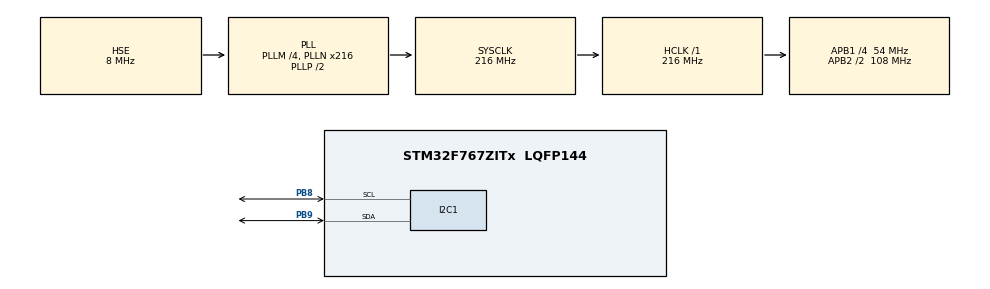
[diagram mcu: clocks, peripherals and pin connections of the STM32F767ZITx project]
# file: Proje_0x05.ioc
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I2C1.Timing=0x20404768
Mcu.Family=STM32F7
Mcu.Name=STM32F767ZITx
Mcu.Package=LQFP144
NVIC.PriorityGroup=NVIC_PRIORITYGROUP_4
PA13.Mode=Serial_Wire
PA13.Signal=SYS_JTMS-SWDIO
PA14.Mode=Serial_Wire
PA14.Signal=SYS_JTCK-SWCLK
PB8.Mode=I2C
PB8.Signal=I2C1_SCL
PB9.Mode=I2C
PB9.Signal=I2C1_SDA
PH0/OSC_IN.Mode=HSE-External-Oscillator
PH0/OSC_IN.Signal=RCC_OSC_IN
PH1/OSC_OUT.Mode=HSE-External-Oscillator
PH1/OSC_OUT.Signal=RCC_OSC_OUT
ProjectManager.HeapSize=0x200
ProjectManager.StackSize=0x400
ProjectManager.TargetToolchain=STM32CubeIDE
RCC.48MHZClocksFreq_Value=24000000
RCC.AHBFreq_Value=216000000
RCC.APB1CLKDivider=RCC_HCLK_DIV4
RCC.APB1Freq_Value=54000000
RCC.APB1TimFreq_Value=108000000
RCC.APB2CLKDivider=RCC_HCLK_DIV2
RCC.APB2Freq_Value=108000000
RCC.APB2TimFreq_Value=216000000
RCC.CortexFreq_Value=216000000
RCC.HCLKFreq_Value=216000000
RCC.HSE_VALUE=8000000
RCC.HSI_VALUE=16000000
RCC.PLLM=4
RCC.PLLMUL=RCC_PLL_MUL9
RCC.PLLN=216
RCC.PLLQ=4
RCC.PLLSourceVirtual=RCC_PLLSOURCE_HSE
RCC.PRESCALERUSB=RCC_USBCLKSOURCE_PLL_DIV1_5
RCC.SYSCLKFreq_VALUE=216000000
RCC.SYSCLKSource=RCC_SYSCLKSOURCE_PLLCLK
RCC.SYSCLKSourceVirtual=RCC_SYSCLKSOURCE_PLLCLK
RCC.USBFreq_Value=108000000
RCC.VCOOutputFreq_Value=432000000
board=NUCLEO-F767ZI

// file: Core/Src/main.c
/* USER CODE BEGIN Header */
/**
 ******************************************************************************
 * @file           : main.c
 * @brief          : Main program body
 ******************************************************************************
 * @attention
 *
 * Copyright (c) 2025 STMicroelectronics.
 * All rights reserved.
 *
 * This software is licensed under terms that can be found in the LICENSE file
 * in the root directory of this software component.
 * If no LICENSE file comes with this software, it is provided AS-IS.
 *
 ******************************************************************************
 */
/* USER CODE END Header */
#include "main.h"

I2C_HandleTypeDef hi2c1;

void SystemClock_Config(void);
static void MX_GPIO_Init(void);
static void MX_I2C1_Init(void);

/* USER CODE BEGIN 0 */
char I2C_Value;
char Read_I2C(char addr) {
	char TX_buff[1];
	char RX_buff[1];
	char I2C_addr = 0xD0;

	TX_buff[0] = addr;

	HAL_I2C_Master_Transmit(&hi2c1, I2C_addr, TX_buff, 1, 10);
	HAL_I2C_Master_Receive(&hi2c1, I2C_addr, RX_buff, 1, 10);

	return RX_buff[0];
}

/* USER CODE END 0 */

int main(void) {

	/* MCU Configuration--------------------------------------------------------*/

	/* Reset of all peripherals, Initializes the Flash interface and the Systick. */
	HAL_Init();

	/* Configure the system clock */
	SystemClock_Config();

	/* Initialize all configured peripherals */
	MX_GPIO_Init();
	MX_I2C1_Init();

	/* Infinite loop */
	while (1) {

		/* USER CODE BEGIN 3 */
		I2C_Value = Read_I2C(0x6B);
		HAL_Delay(500);
		I2C_Value = Read_I2C(0x75);
		HAL_Delay(500);
	}
	/* USER CODE END 3 */
}

void SystemClock_Config(void) {
	RCC_OscInitTypeDef RCC_OscInitStruct = { 0 };
	RCC_ClkInitTypeDef RCC_ClkInitStruct = { 0 };

	/** Configure the main internal regulator output voltage
	 */
	__HAL_RCC_PWR_CLK_ENABLE();
	__HAL_PWR_VOLTAGESCALING_CONFIG(PWR_REGULATOR_VOLTAGE_SCALE1);

	/** Initializes the RCC Oscillators according to the specified parameters
	 * in the RCC_OscInitTypeDef structure.
	 */
	RCC_OscInitStruct.OscillatorType = RCC_OSCILLATORTYPE_HSE;
	RCC_OscInitStruct.HSEState = RCC_HSE_ON;
	RCC_OscInitStruct.PLL.PLLState = RCC_PLL_ON;
	RCC_OscInitStruct.PLL.PLLSource = RCC_PLLSOURCE_HSE;
	RCC_OscInitStruct.PLL.PLLM = 4;
	RCC_OscInitStruct.PLL.PLLN = 216;
	RCC_OscInitStruct.PLL.PLLP = RCC_PLLP_DIV2;
	RCC_OscInitStruct.PLL.PLLQ = 4;
	RCC_OscInitStruct.PLL.PLLR = 2;
	if (HAL_RCC_OscConfig(&RCC_OscInitStruct) != HAL_OK) {
		Error_Handler();
	}

	/** Activate the Over-Drive mode
	 */
	if (HAL_PWREx_EnableOverDrive() != HAL_OK) {
		Error_Handler();
	}

	/** Initializes the CPU, AHB and APB buses clocks
	 */
	RCC_ClkInitStruct.ClockType = RCC_CLOCKTYPE_HCLK | RCC_CLOCKTYPE_SYSCLK
			| RCC_CLOCKTYPE_PCLK1 | RCC_CLOCKTYPE_PCLK2;
	RCC_ClkInitStruct.SYSCLKSource = RCC_SYSCLKSOURCE_PLLCLK;
	RCC_ClkInitStruct.AHBCLKDivider = RCC_SYSCLK_DIV1;
	RCC_ClkInitStruct.APB1CLKDivider = RCC_HCLK_DIV4;
	RCC_ClkInitStruct.APB2CLKDivider = RCC_HCLK_DIV2;

	if (HAL_RCC_ClockConfig(&RCC_ClkInitStruct, FLASH_LATENCY_7) != HAL_OK) {
		Error_Handler();
	}
}

static void MX_I2C1_Init(void) {

	hi2c1.Instance = I2C1;
	hi2c1.Init.Timing = 0x20404768;
	hi2c1.Init.OwnAddress1 = 0;
	hi2c1.Init.AddressingMode = I2C_ADDRESSINGMODE_7BIT;
	hi2c1.Init.DualAddressMode = I2C_DUALADDRESS_DISABLE;
	hi2c1.Init.OwnAddress2 = 0;
	hi2c1.Init.OwnAddress2Masks = I2C_OA2_NOMASK;
	hi2c1.Init.GeneralCallMode = I2C_GENERALCALL_DISABLE;
	hi2c1.Init.NoStretchMode = I2C_NOSTRETCH_DISABLE;
	if (HAL_I2C_Init(&hi2c1) != HAL_OK) {
		Error_Handler();
	}

	/** Configure Analogue filter
	 */
	if (HAL_I2CEx_ConfigAnalogFilter(&hi2c1, I2C_ANALOGFILTER_ENABLE)
			!= HAL_OK) {
		Error_Handler();
	}

	/** Configure Digital filter
	 */
	if (HAL_I2CEx_ConfigDigitalFilter(&hi2c1, 0) != HAL_OK) {
		Error_Handler();
	}

}

static void MX_GPIO_Init(void) {

	/* GPIO Ports Clock Enable */
	__HAL_RCC_GPIOH_CLK_ENABLE();
	__HAL_RCC_GPIOA_CLK_ENABLE();
	__HAL_RCC_GPIOB_CLK_ENABLE();

}

void Error_Handler(void) {
	__disable_irq();
	while (1) {
	}
}
